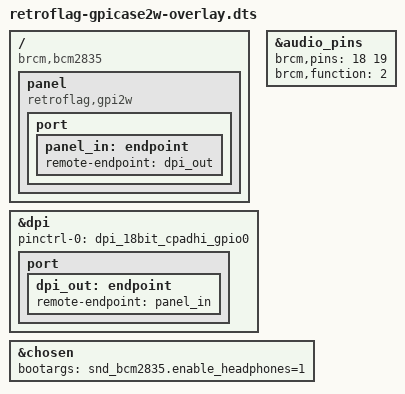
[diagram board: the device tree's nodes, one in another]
/*
 * vc4-kms-dpi-a030vvn01-1-overlay.dts
 */

/dts-v1/;
/plugin/;

/ {
    compatible = "brcm,bcm2835";

    fragment@0 {
        target-path = "/";
        __overlay__ {
            panel: panel {
                compatible = "retroflag,gpi2w", "simple-panel";

                port {
                    panel_in: endpoint {
                        remote-endpoint = <&dpi_out>;
                    };
                };
            };
        };
    };

    fragment@1 {
        target = <&dpi>;
        __overlay__  {
            status = "okay";

            pinctrl-names = "default";
            pinctrl-0 = <&dpi_18bit_cpadhi_gpio0>;

            port {
                dpi_out: endpoint {
                    remote-endpoint = <&panel_in>;
                };
            };
        };
    };

    fragment@2 {
        target = <&audio_pins>;
        __overlay__ {
            brcm,pins = < 18 19 >;
            brcm,function = < 2 >; /* alt5 alt5 */
        };
    };

    fragment@3 {
        target = <&chosen>;
        __overlay__  {
            bootargs = "snd_bcm2835.enable_headphones=1";
        };
    };
};
